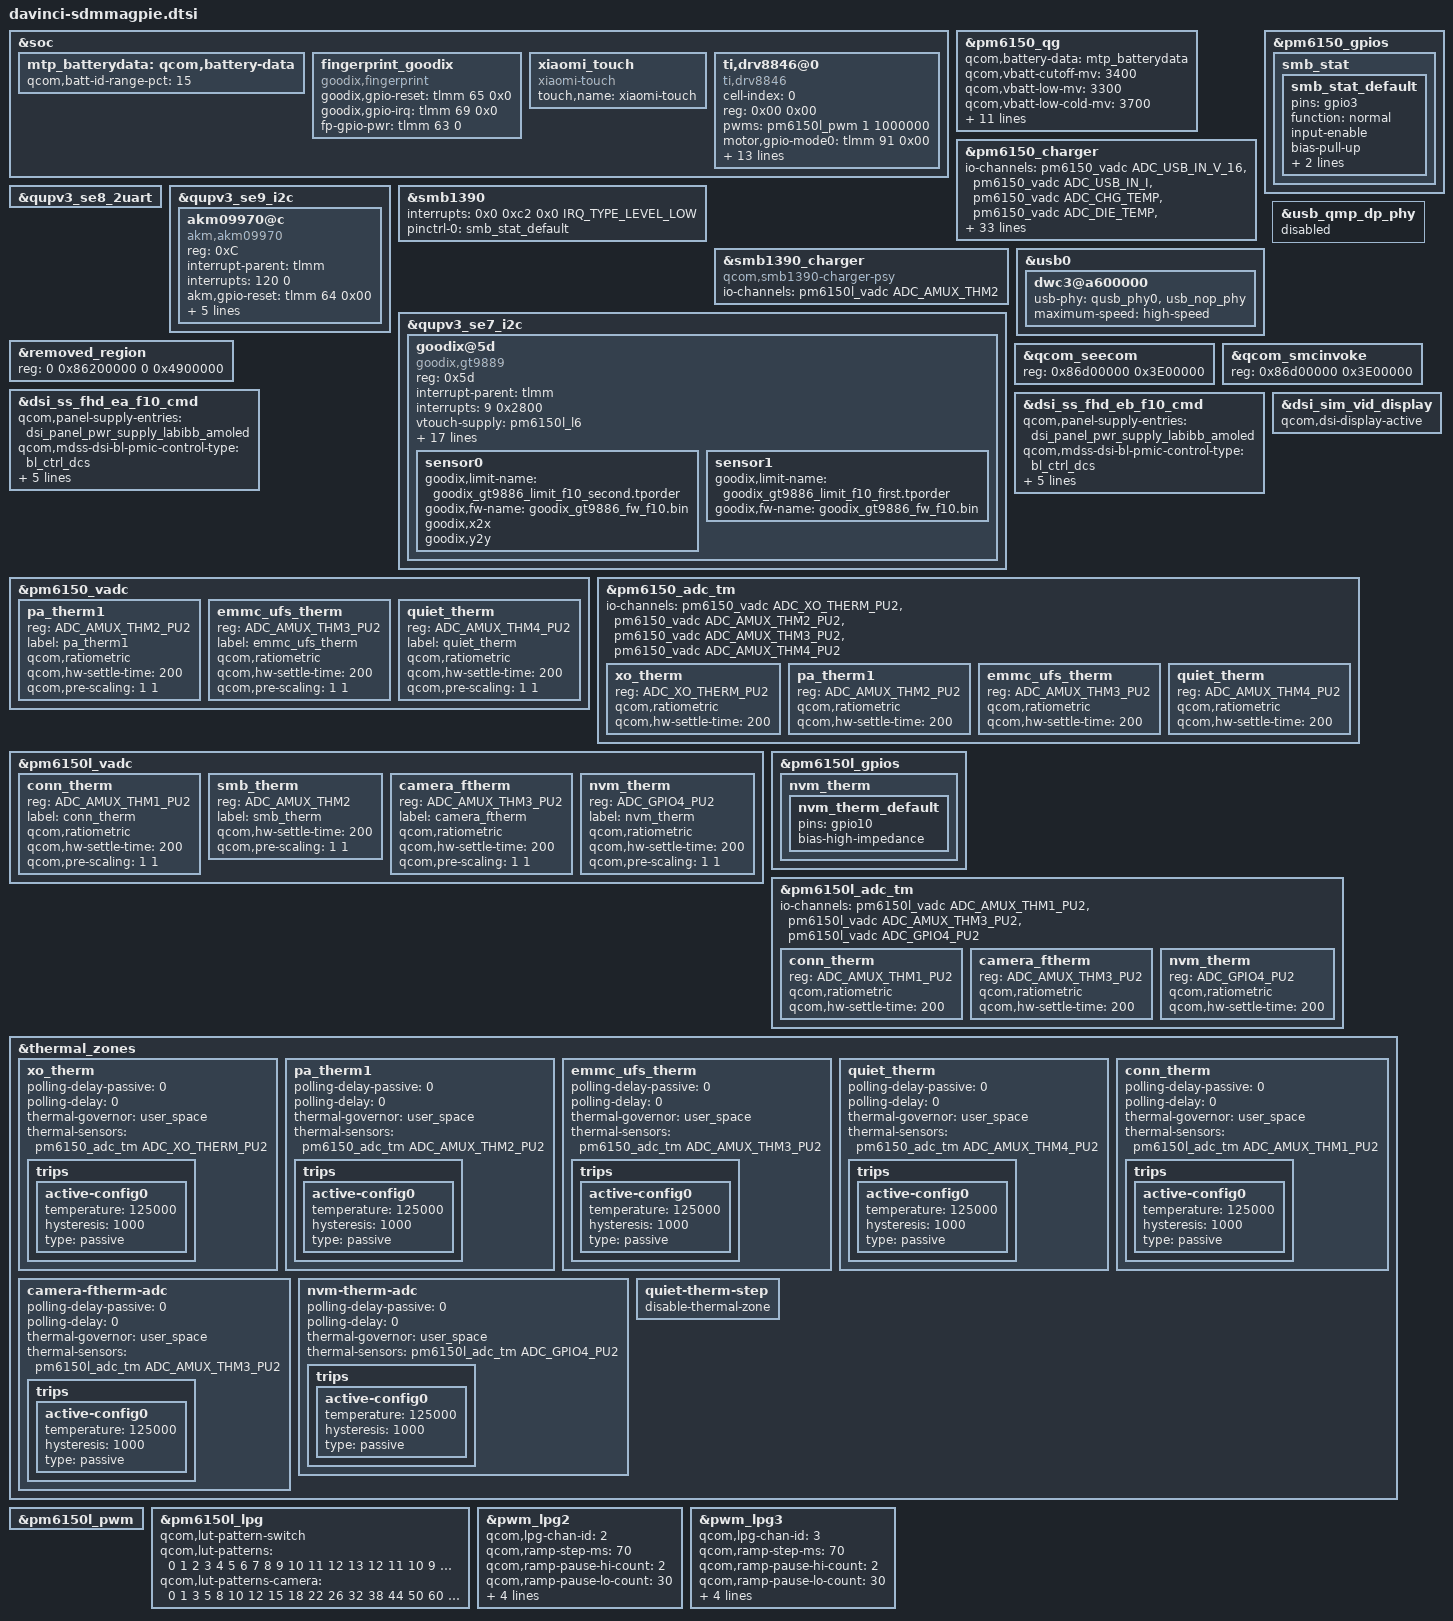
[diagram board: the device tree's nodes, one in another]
/*
this file is for attribution only of aquila
And public attribution of xiaomi platforms(like F3 and so and)
*/

#include "davinci-sdmmagpie-pinctrl.dtsi"
#include "xiaomi-sdmmagpie-common.dtsi"
#include "davinci-sdmmagpie-camera-sensor.dtsi"

&soc {
        mtp_batterydata: qcom,battery-data {
		qcom,batt-id-range-pct = <15>;
                #include "batterydata-F10-coslight-4000mah.dtsi"
                #include "batterydata-F10-sunwoda-4000mah.dtsi"
        };
};

&pm6150_qg {
	qcom,battery-data = <&mtp_batterydata>;
	qcom,vbatt-cutoff-mv = <3400>;
	qcom,vbatt-low-mv = <3300>;
	qcom,vbatt-low-cold-mv = <3700>;
	qcom,vbatt-empty-mv = <3100>;
	qcom,vbatt-empty-cold-mv = <3100>;
	qcom,s3-entry-fifo-length = <2>;
	qcom,s3-entry-ibat-ua = <25000>;
	qcom,s3-exit-ibat-ua = <45000>;
	qcom,qg-iterm-ma = <350>;
	qcom,hold-soc-while-full;
	qcom,linearize-soc;
	qcom,cl-feedback-on;
	qcom,shutdown-soc-threshold = <3>;
	qcom,shutdown-delay-enable;
};

&pm6150_charger {
	io-channels = <&pm6150_vadc ADC_USB_IN_V_16>,
		      <&pm6150_vadc ADC_USB_IN_I>,
		      <&pm6150_vadc ADC_CHG_TEMP>,
		      <&pm6150_vadc ADC_DIE_TEMP>,
		      <&pm6150l_vadc ADC_AMUX_THM1_PU2>,
		      <&pm6150_vadc ADC_SBUx>,
		      <&pm6150_vadc ADC_VPH_PWR>;
	io-channel-names = "usb_in_voltage",
			   "usb_in_current",
			   "chg_temp",
			   "die_temp",
			   "conn_temp",
			   "sbux_res",
			   "vph_voltage";
	qcom,battery-data = <&mtp_batterydata>;
	qcom,usb-icl-ua = <2800000>;
	qcom,fcc-max-ua = <3500000>;
	qcom,fv-max-uv = <4400000>;
	qcom,auto-recharge-soc = <99>;
	qcom,chg-term-src = <1>;
	qcom,chg-term-current-ma = <(-200)>;
	qcom,sec-charger-config = <1>;
	qcom,dynamic-fv-enable;
	qcom,thermal-mitigation = <3500000 3400000 3300000 3200000 3100000 3000000 2900000
				   2800000 2600000 2400000 2200000 2000000 1800000 1500000
				   1000000 500000>;
	qcom,thermal-mitigation-icl
				 = <2800000 2700000 2600000 2400000 2200000 2100000 2000000
				   2000000 2000000 1900000 1800000 1600000 1500000 1300000
				   1000000 750000>;
	qcom,thermal-mitigation-dcp
				= <1800000 1800000 1800000 1800000 1800000 1800000 1800000
				   1800000 1800000 1700000 1600000 1400000 1200000 1100000
				   1100000 1000000>;
	qcom,thermal-mitigation-qc2
				= <1500000 1500000 1500000 1500000 1450000 1400000 1350000
				   1300000 1150000 1100000 1000000 900000 850000 750000
				   650000 500000>;
	qcom,thermal-fcc-qc3-normal
				= <3500000 3400000 3300000 3200000 3100000 3000000 2900000
				   2800000 2700000 2600000 2400000 2200000 2000000 2000000
				   750000 700000>;
	qcom,thermal-fcc-qc3-cp
				= <3500000 3500000 3500000 3500000 3400000 3300000 3200000
				   3100000 3000000 2800000 2600000 2400000 2200000 2000000
				   1000000 700000>;
	qcom,thermal-mitigation-pd-base
				= <3500000 3500000 3500000 3500000 3400000 3300000 3200000
				   3100000 3000000 2800000 2600000 2400000 2200000 2000000
				   1000000 700000>;
	qcom,thermal-fcc-pps-cp
				= <3500000 3500000 3500000 3500000 3400000 3300000 3200000
				   3100000 3000000 2800000 2600000 2400000 2200000 2000000
				   1000000 700000>;
	dpdm-supply = <&qusb_phy0>;
	qcom,sw-jeita-enable;
	qcom,step-charging-enable;
	qcom,lpd-disable;
	mi,early-status-report;
};

&pm6150_gpios {
	smb_stat {
		smb_stat_default: smb_stat_default {
			pins = "gpio3";
			function = "normal";
			input-enable;
			bias-pull-up;
			qcom,pull-up-strength = <PMIC_GPIO_PULL_UP_30>;
			power-source = <0>;
		};
	};
};

&qupv3_se8_2uart {
	status = "ok";
};

&qupv3_se9_i2c {
	status = "ok";
	/* FCAM Digital HALL */
	akm09970@c {
		compatible = "akm,akm09970";
		reg = <0xC>;
		interrupt-parent = <&tlmm>;
		interrupts = <120 0>;
		akm,gpio-reset = <&tlmm 64 0x00>;
		akm,gpio-irq = <&tlmm 93 0x00>;
		akm,measure-freq-hz = <100>;
		vdd-supply = <&pm6150l_l8>;

		pinctrl-names = "akm09970_gpio_active", "akm09970_gpio_suspend";
		pinctrl-0 = <&akm_irq_active &akm_reset_active>;
		pinctrl-1 = <&akm_irq_suspend &akm_reset_suspend>;
		status = "ok";
	};
	#include "smb1390.dtsi"
};

&smb1390 {
	/delete-property/ interrupts;
	interrupts = <0x0 0xc2 0x0 IRQ_TYPE_LEVEL_LOW>;
	pinctrl-names = "default";
	pinctrl-0 = <&smb_stat_default>;
	status = "ok";
};

&smb1390_charger {
	compatible = "qcom,smb1390-charger-psy";
	io-channels = <&pm6150l_vadc ADC_AMUX_THM2>;
	io-channel-names = "cp_die_temp";
	status = "ok";
};

&usb0 {
	dwc3@a600000 {
		usb-phy = <&qusb_phy0>, <&usb_nop_phy>;
		maximum-speed = "high-speed";
	};
};

&usb_qmp_dp_phy {
	status = "disabled";
};

&soc {
	fingerprint_goodix {
		compatible = "goodix,fingerprint";
		goodix,gpio-reset = <&tlmm 65 0x0>;
		goodix,gpio-irq = <&tlmm 69 0x0>;
		fp-gpio-pwr = <&tlmm 63 0>;
		status = "ok";
	};
};

&qupv3_se7_i2c{
	status = "ok";
	goodix@5d {
		compatible = "goodix,gt9889";
		reg = <0x5d>;
		status = "ok";
		interrupt-parent = <&tlmm>;
		interrupts = <9 0x2800>;
		vtouch-supply = <&pm6150l_l6>;//3.3v
		//iotouch-supply = <&pm6150_l10>;
		vtouch-load = <600000>;
		pinctrl-names = "pmx_ts_active","pmx_ts_suspend";
		pinctrl-0 = <&tp_active>;
		pinctrl-1 = <&tp_int_suspend &tp_reset_suspend>;
		goodix,reset-gpio = <&tlmm 8 0x0>;
		goodix,irq-gpio = <&tlmm 9 0x2800>;
		//goodix,vdd-gpio = <&tlmm 98 0x0>;			/* 3v3 */
		goodix,avdd-gpio = <&tlmm 5 0x0>;			/* 1v8 */
		goodix,irq-flags = <2>; /* 1:trigger rising, 2:trigger falling;*/
		goodix,panel-max-id = <10>;
		goodix,panel-max-x = <1079>;
		goodix,panel-max-y = <2339>;
		goodix,panel-max-w = <127>;
		goodix,panel-max-p = <127>;
		goodix,panel-max-fod = <127>;
	/*	goodix,panel-key-map = <158 172 217>; */ /*KEY_BACK, KEY_HOMEPAGE, KEY_SEARCH*/
		goodix,power-on-delay-us = <300000>; /*300ms*/
		goodix,power-off-delay-us = <5000>;
		goodix,cfg-name = "goodix_gt9886_cfg_f10.bin";
		normal-cfg = [
				];
	/*	goodix,swap-axis; */
	/*	goodix,pen-enable; */
	/*	goodix,key-of-pen = <331 332>; */ /*BTN_STYLUS, BTN_STYLUS2*/
		sensor0 {
				goodix,limit-name = "goodix_gt9886_limit_f10_second.tporder";
				goodix,fw-name = "goodix_gt9886_fw_f10.bin";
				goodix,x2x;
				goodix,y2y;
		};
		sensor1 {
				goodix,limit-name = "goodix_gt9886_limit_f10_first.tporder";
				goodix,fw-name = "goodix_gt9886_fw_f10.bin";
		};
	};
};

&soc {
	xiaomi_touch {
		compatible = "xiaomi-touch";
		status = "ok";
		touch,name = "xiaomi-touch";
	};
};

/* Enlarge TZ memory size to 62M */
&removed_region {
	reg = <0 0x86200000 0 0x4900000>;
};

&qcom_seecom {
	reg = <0x86d00000 0x3E00000>;
};

&qcom_smcinvoke {
	reg = <0x86d00000 0x3E00000>;
};

&dsi_ss_fhd_ea_f10_cmd {
        qcom,panel-supply-entries = <&dsi_panel_pwr_supply_labibb_amoled>;
        qcom,mdss-dsi-bl-pmic-control-type = "bl_ctrl_dcs";
        qcom,mdss-dsi-bl-min-level = <2>;
        qcom,mdss-dsi-bl-max-level = <2047>;
        qcom,mdss-dsi-mode-sel-gpio-state = "single_port";
        //qcom,panel-mode-gpio = <&tlmm 7 0>;
        qcom,platform-te-gpio = <&tlmm 10 0>;
        qcom,platform-reset-gpio = <&pm6150l_gpios 9 0>;
};

&dsi_ss_fhd_eb_f10_cmd {
	qcom,panel-supply-entries = <&dsi_panel_pwr_supply_labibb_amoled>;
	qcom,mdss-dsi-bl-pmic-control-type = "bl_ctrl_dcs";
	qcom,mdss-dsi-bl-min-level = <256>;
	qcom,mdss-dsi-bl-max-level = <4095>;
	qcom,mdss-dsi-mode-sel-gpio-state = "single_port";
	//qcom,panel-mode-gpio = <&tlmm 7 0>;
	qcom,platform-te-gpio = <&tlmm 10 0>;
	qcom,platform-reset-gpio = <&pm6150l_gpios 9 0>;
};

&dsi_sim_vid_display {
        qcom,dsi-display-active;
};

&pm6150_vadc {
	pa_therm1 {
		reg = <ADC_AMUX_THM2_PU2>;
		label = "pa_therm1";
		qcom,ratiometric;
		qcom,hw-settle-time = <200>;
		qcom,pre-scaling = <1 1>;
	};

	emmc_ufs_therm {
		reg = <ADC_AMUX_THM3_PU2>;
		label = "emmc_ufs_therm";
		qcom,ratiometric;
		qcom,hw-settle-time = <200>;
		qcom,pre-scaling = <1 1>;
	};

	quiet_therm {
		reg = <ADC_AMUX_THM4_PU2>;
		label = "quiet_therm";
		qcom,ratiometric;
		qcom,hw-settle-time = <200>;
		qcom,pre-scaling = <1 1>;
	};
};

&pm6150_adc_tm {
	io-channels = <&pm6150_vadc ADC_XO_THERM_PU2>,
			<&pm6150_vadc ADC_AMUX_THM2_PU2>,
			<&pm6150_vadc ADC_AMUX_THM3_PU2>,
			<&pm6150_vadc ADC_AMUX_THM4_PU2>;

	/* Channel nodes */
	xo_therm {
		reg = <ADC_XO_THERM_PU2>;
		qcom,ratiometric;
		qcom,hw-settle-time = <200>;
	};

	pa_therm1 {
		reg = <ADC_AMUX_THM2_PU2>;
		qcom,ratiometric;
		qcom,hw-settle-time = <200>;
	};

	emmc_ufs_therm {
		reg = <ADC_AMUX_THM3_PU2>;
		qcom,ratiometric;
		qcom,hw-settle-time = <200>;
	};

	quiet_therm {
		reg = <ADC_AMUX_THM4_PU2>;
		qcom,ratiometric;
		qcom,hw-settle-time = <200>;
	};
};

&pm6150l_vadc {

	conn_therm {
		reg = <ADC_AMUX_THM1_PU2>;
		label = "conn_therm";
		qcom,ratiometric;
		qcom,hw-settle-time = <200>;
		qcom,pre-scaling = <1 1>;
	};

	smb_therm {
		reg = <ADC_AMUX_THM2>;
		label = "smb_therm";
		qcom,hw-settle-time = <200>;
		qcom,pre-scaling = <1 1>;
	};

	camera_ftherm {
		reg = <ADC_AMUX_THM3_PU2>;
		label = "camera_ftherm";
		qcom,ratiometric;
		qcom,hw-settle-time = <200>;
		qcom,pre-scaling = <1 1>;
	};

	nvm_therm {
		reg = <ADC_GPIO4_PU2>;
		label = "nvm_therm";
		qcom,ratiometric;
		qcom,hw-settle-time = <200>;
		qcom,pre-scaling = <1 1>;
	};
};

&pm6150l_gpios {
	nvm_therm {
		nvm_therm_default: nvm_therm_default {
			pins = "gpio10";
			bias-high-impedance;
		};
	};
};

&pm6150l_adc_tm {
	io-channels = <&pm6150l_vadc ADC_AMUX_THM1_PU2>,
			<&pm6150l_vadc ADC_AMUX_THM3_PU2>,
			<&pm6150l_vadc ADC_GPIO4_PU2>;

	/* Channel nodes */
	conn_therm {
		reg = <ADC_AMUX_THM1_PU2>;
		qcom,ratiometric;
		qcom,hw-settle-time = <200>;
	};

	camera_ftherm {
		reg = <ADC_AMUX_THM3_PU2>;
		qcom,ratiometric;
		qcom,hw-settle-time = <200>;
	};

	nvm_therm {
		reg = <ADC_GPIO4_PU2>;
		qcom,ratiometric;
		qcom,hw-settle-time = <200>;
	};
};

&thermal_zones {

	xo_therm {
		polling-delay-passive = <0>;
		polling-delay = <0>;
		thermal-governor = "user_space";
		thermal-sensors = <&pm6150_adc_tm ADC_XO_THERM_PU2>;
		trips {
			active-config0 {
				temperature = <125000>;
				hysteresis = <1000>;
				type = "passive";
			};
		};
	};

	pa_therm1 {
		polling-delay-passive = <0>;
		polling-delay = <0>;
		thermal-governor = "user_space";
		thermal-sensors = <&pm6150_adc_tm ADC_AMUX_THM2_PU2>;
		trips {
			active-config0 {
				temperature = <125000>;
				hysteresis = <1000>;
				type = "passive";
			};
		};
	};

	emmc_ufs_therm {
		polling-delay-passive = <0>;
		polling-delay = <0>;
		thermal-governor = "user_space";
		thermal-sensors = <&pm6150_adc_tm ADC_AMUX_THM3_PU2>;
		trips {
			active-config0 {
				temperature = <125000>;
				hysteresis = <1000>;
				type = "passive";
			};
		};
	};

	quiet_therm {
		polling-delay-passive = <0>;
		polling-delay = <0>;
		thermal-governor = "user_space";
		thermal-sensors = <&pm6150_adc_tm ADC_AMUX_THM4_PU2>;
		trips {
			active-config0 {
				temperature = <125000>;
				hysteresis = <1000>;
				type = "passive";
			};
		};
	};

	conn_therm {
		polling-delay-passive = <0>;
		polling-delay = <0>;
		thermal-governor = "user_space";
		thermal-sensors = <&pm6150l_adc_tm ADC_AMUX_THM1_PU2>;
		trips {
			active-config0 {
				temperature = <125000>;
				hysteresis = <1000>;
				type = "passive";
			};
		};
	};

	camera-ftherm-adc {
		polling-delay-passive = <0>;
		polling-delay = <0>;
		thermal-governor = "user_space";
		thermal-sensors = <&pm6150l_adc_tm ADC_AMUX_THM3_PU2>;
		trips {
			active-config0 {
				temperature = <125000>;
				hysteresis = <1000>;
				type = "passive";
			};
		};
	};

	nvm-therm-adc {
		polling-delay-passive = <0>;
		polling-delay = <0>;
		thermal-governor = "user_space";
		thermal-sensors = <&pm6150l_adc_tm ADC_GPIO4_PU2>;
		trips {
			active-config0 {
				temperature = <125000>;
				hysteresis = <1000>;
				type = "passive";
			};
		};
	};

	quiet-therm-step {
		disable-thermal-zone;
	};
};

/* Front motor */
&pm6150l_pwm {
	status = "ok";
};

&soc {
	ti,drv8846@0 {
		cell-index = <0>;
		reg = <0x00 0x00>;
		compatible = "ti,drv8846";
		pwms = <&pm6150l_pwm 1 1000000>;
		motor,gpio-mode0 = <&tlmm 91 0x00>;
		motor,gpio-mode1 = <&tlmm 66 0x00>;
		motor,gpio-sleep = <&tlmm 88 0x00>;
		motor,gpio-dir = <&tlmm 55 0x00>;
		motor,gpio-pwren = <&tlmm 90 0x00>;

		motor,rampup-pwm-period-ns = <625000>;
		motor,rampup-duration-ms = <50>;
		motor,high-pwm-period-ns = <52083>;
		motor,high-duration-ms = <720>;
		motor,rampdown-pwm-period-ns = <625000>;
		motor,rampdown-duration-ms = <50>;
		motor,step-mode = <2>;

		pinctrl-names = "default";
		pinctrl-0 = <&pwm_out_gpio10_default &motor_gpio_default &motor_gpio_fault>;
		status = "ok";
	};
};

&pm6150l_lpg {
	qcom,lut-pattern-switch;
	qcom,lut-patterns = <0 1 2 3 4 5 6 7 8 9 10 11 12 13
				12 11 10 9 8 7 6 5 4 3 2 1 0>;
	qcom,lut-patterns-camera = <0 1 3 5 8 10 12 15 18 22 26 32 38 44 50 60 72 82 90 96 98 99 100
				99 98 96 90 82 72 60 50 44 38 32 26 22 18 15 12 10 8 5 3 1 0>;
};

&pwm_lpg2 {
	qcom,lpg-chan-id = <2>;
	qcom,ramp-step-ms = <70>;
	qcom,ramp-pause-hi-count = <2>;
	qcom,ramp-pause-lo-count = <30>;
	qcom,ramp-low-index = <0>;
	qcom,ramp-high-index = <26>;
	qcom,ramp-from-low-to-high;
	qcom,ramp-pattern-repeat;
};

&pwm_lpg3 {
	qcom,lpg-chan-id = <3>;
	qcom,ramp-step-ms = <70>;
	qcom,ramp-pause-hi-count = <2>;
	qcom,ramp-pause-lo-count = <30>;
	qcom,ramp-low-index = <0>;
	qcom,ramp-high-index = <26>;
	qcom,ramp-from-low-to-high;
	qcom,ramp-pattern-repeat;
};
